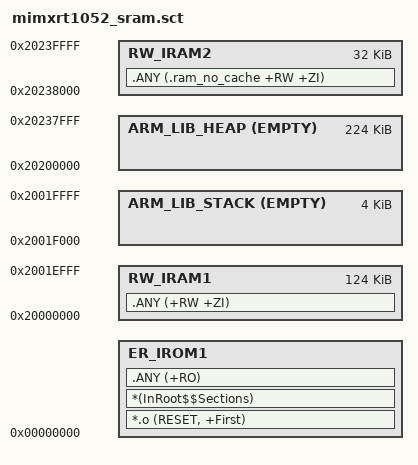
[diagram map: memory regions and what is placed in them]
;*********************************************************************
;* i.MX RT1052 linker scatter file (running code from internal SRAM) *
;*********************************************************************

LR_IROM1 0x00000000 0x20000
{
   ER_IROM1 0x00000000
   {
      *.o (RESET, +First)
      *(InRoot$$Sections)
      .ANY (+RO)
   }
   
   RW_IRAM1 0x20000000 0x1F000
   {
      .ANY (+RW +ZI)
   }
   
   ARM_LIB_STACK 0x20020000 EMPTY -0x1000
   {
   }
   
   ARM_LIB_HEAP 0x20200000 EMPTY 0x38000
   {
   }
   
   RW_IRAM2 0x20238000 0x8000
   {
      .ANY (.ram_no_cache +RW +ZI)
   }
}
